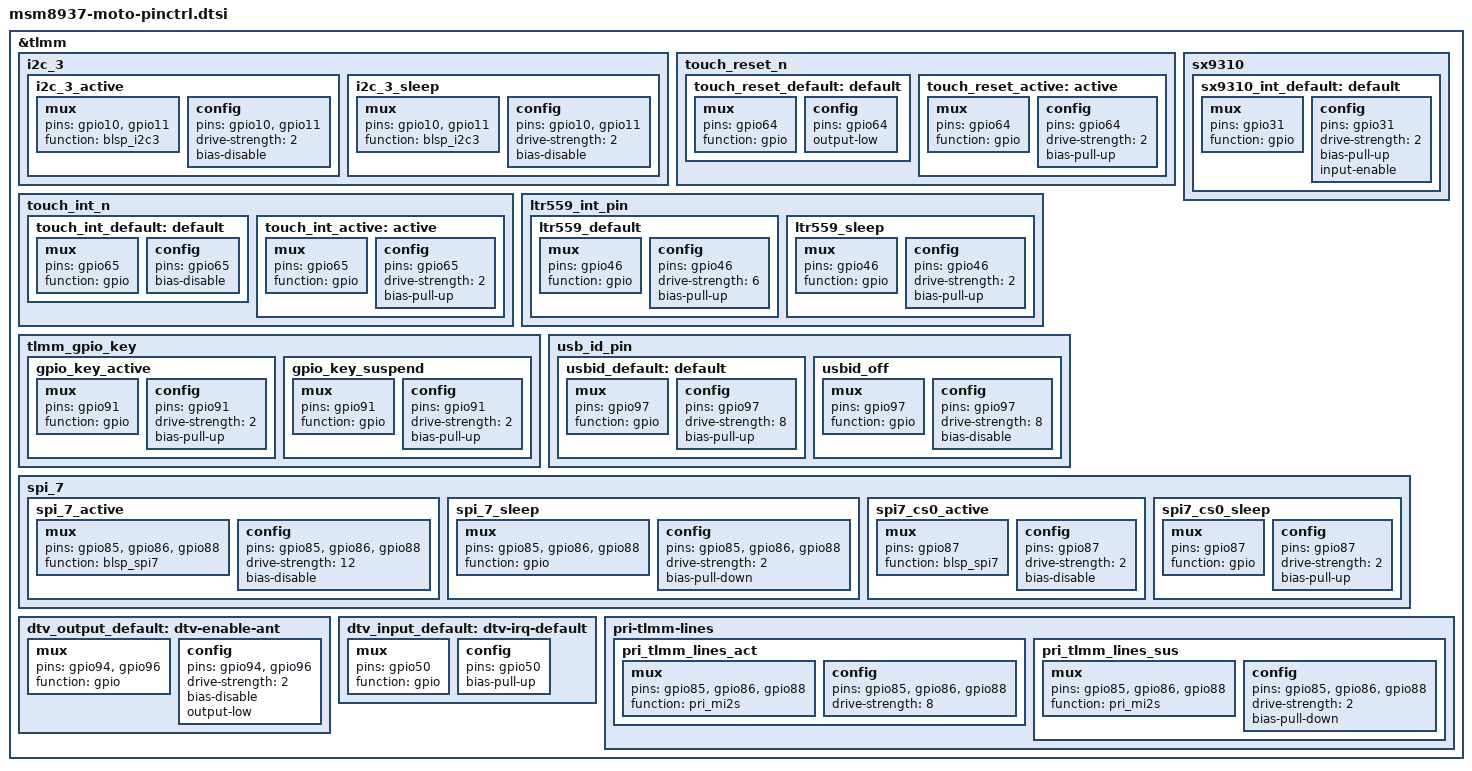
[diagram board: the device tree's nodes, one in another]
/* Copyright (c) 2016, Motorola Mobility Inc. All rights reserved.
 *
 * This program is free software; you can redistribute it and/or modify
 * it under the terms of the GNU General Public License version 2 and
 * only version 2 as published by the Free Software Foundation.
 *
 * This program is distributed in the hope that it will be useful,
 * but WITHOUT ANY WARRANTY; without even the implied warranty of
 * MERCHANTABILITY or FITNESS FOR A PARTICULAR PURPOSE.  See the
 * GNU General Public License for more details.
 */

&tlmm{
	i2c_3 {
		i2c_3_active: i2c_3_active {
			/* active state */
			mux {
				pins = "gpio10", "gpio11";
				function = "blsp_i2c3";
			};

			config {
				pins = "gpio10", "gpio11";
				drive-strength = <2>;
				bias-disable;
			};
		};

		i2c_3_sleep: i2c_3_sleep {
			/* suspended state */
			mux {
				pins = "gpio10", "gpio11";
				function = "blsp_i2c3";
			};

			config {
				pins = "gpio10", "gpio11";
				drive-strength = <2>;
				bias-disable;
			};
		};
	};

	touch_reset_n {
		/*label = "touch-reset";*/

		touch_reset_default: default {
			mux {
				pins = "gpio64";
				function = "gpio";
			};

			config {
				pins = "gpio64";
				output-low;
			};
		};

		touch_reset_active: active {
			mux {
				pins = "gpio64";
				function = "gpio";
			};

			config {
				pins = "gpio64";
				drive-strength = <2>;   /* 2 mA */
				bias-pull-up; /* pull-up */
			};
		};
	};

	touch_int_n {
		/*label = "touch-int";*/

		touch_int_default: default {
			mux {
				pins = "gpio65";
				function = "gpio";
			};

			config {
				pins = "gpio65";
				bias-disable;
			};
		};

		touch_int_active: active {
			mux {
				pins = "gpio65";
				function = "gpio";
			};

			config {
				pins = "gpio65";
				drive-strength = <2>;
				bias-pull-up; /* pull-up */
			};
		};
	};

	sx9310 {
		sx9310_int_default: default {
			    mux {
				    pins = "gpio31";
				    function = "gpio";
			    };

			    config {
				    pins = "gpio31";
				    drive-strength = <2>;
				    bias-pull-up;
				    input-enable;
			    };
		    };
	};

	ltr559_int_pin {
		ltr559_default: ltr559_default {
			mux {
				pins = "gpio46";
				function = "gpio";
			};
			config {
				pins = "gpio46";
				drive-strength = <6>;
				bias-pull-up;
			};
		};
		ltr559_sleep: ltr559_sleep {
		      mux {
			      pins = "gpio46";
			      function = "gpio";
		      };
		      config {
			      pins = "gpio46";
			      drive-strength = <2>;
			      bias-pull-up;
		      };
	      };
	};

	tlmm_gpio_key {
		gpio_key_active: gpio_key_active {
			mux {
				pins = "gpio91";
				function = "gpio";
			};

			config {
				pins = "gpio91";
				drive-strength = <2>;
				bias-pull-up;
			};
		};

		gpio_key_suspend: gpio_key_suspend {
			mux {
				pins = "gpio91";
				function = "gpio";
			};

			config {
				pins = "gpio91";
				drive-strength = <2>;
				bias-pull-up;
			};
		};
	};

	usb_id_pin {
		usbid_default: default {
			mux {
				pins = "gpio97";
				function = "gpio";
			};
			config {
				pins = "gpio97";
				drive-strength = <8>;
				bias-pull-up;
			};
		};
		usbid_off: usbid_off {
			mux {
				pins = "gpio97";
				function = "gpio";
			};
			config {
				pins = "gpio97";
				drive-strength = <8>;
				bias-disable;
			};
		};
	};

	spi_7 {
		/* BLSP7 MOSI, MISO, CLK */
		spi_7_active: spi_7_active {
			/* active state */
			mux {
				/* MOSI, MISO, CLK */
				pins = "gpio85", "gpio86", "gpio88";
				function = "blsp_spi7";
			};
			config {
				pins = "gpio85", "gpio86", "gpio88";
				drive-strength = <12>; /* 12 MA */
				bias-disable; /* No PULL */
			};
		};

		spi_7_sleep:spi_7_sleep {
			mux {
				/* MOSI, MISO, CLK */
				pins = "gpio85", "gpio86", "gpio88";
				function = "gpio";
			};
			config {
				pins = "gpio85", "gpio86", "gpio88";
				drive-strength = <2>; /* 2 MA */
				bias-pull-down; /* PULL Down */
			};
		};

		spi7_cs0_active: spi7_cs0_active {
			/* CS */
			mux {
				pins = "gpio87";
				function = "blsp_spi7";
			};
			config {
				pins = "gpio87";
				drive-strength = <2>;
				bias-disable;
			};
		};

		spi7_cs0_sleep: spi7_cs0_sleep {
			/* CS */
			mux {
				pins = "gpio87";
				function = "gpio";
			};
			config {
				pins = "gpio87";
				drive-strength = <2>;
				bias-pull-up;
			};
		};
	};

	/* DTV ldo enable and ant Switch pin */
	dtv_output_default: dtv-enable-ant {
		mux {
			/* enable, reset */
			pins = "gpio94", "gpio96";
			function = "gpio";
		};
		config {
			pins = "gpio94", "gpio96";
			drive-strength = <2>; /* 2 MA */
			bias-disable ; /* No PULL */
			output-low;
		};
	};
	/* DTV interrupt pin */
	dtv_input_default: dtv-irq-default {
			mux {
				pins = "gpio50";
				function = "gpio";
			};
			config {
				pins = "gpio50";
				bias-pull-up; /* pull up */
			};
	};

	/delete-node/ pri-tlmm-lines;
	pri-tlmm-lines {
		pri_tlmm_lines_act: pri_tlmm_lines_act {
			mux {
				pins = "gpio85", "gpio86", "gpio88";
				function = "pri_mi2s";
			};

			config {
				pins = "gpio85", "gpio86", "gpio88";
				drive-strength = <8>;
			};
		};

		pri_tlmm_lines_sus: pri_tlmm_lines_sus {
			mux {
				pins = "gpio85", "gpio86", "gpio88";
				function = "pri_mi2s";
			};

			config {
				pins = "gpio85", "gpio86", "gpio88";
				drive-strength = <2>;
				bias-pull-down;
			};
		};
	};
};
